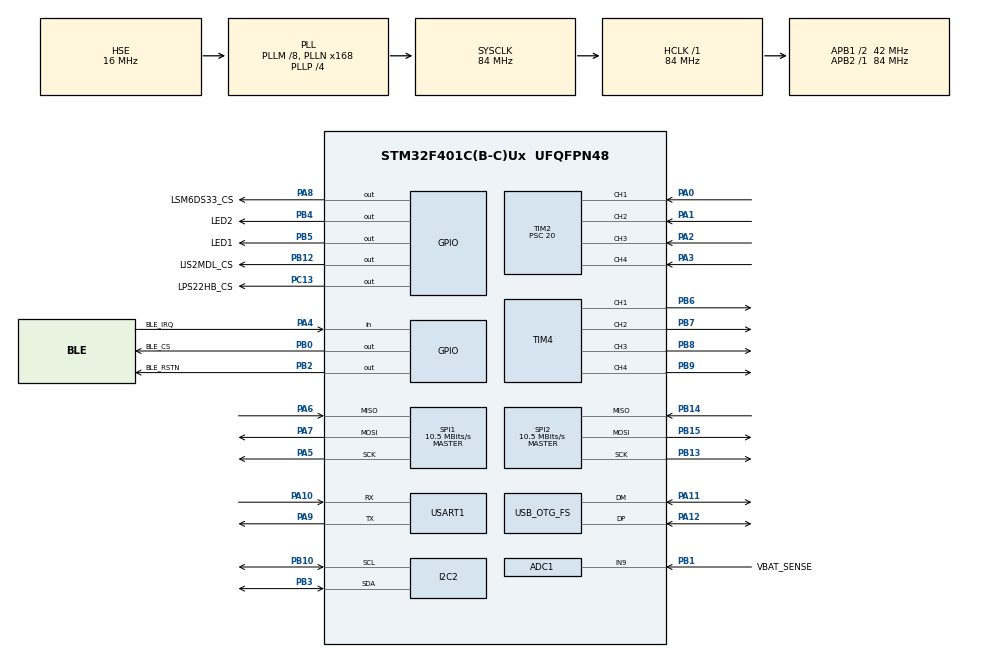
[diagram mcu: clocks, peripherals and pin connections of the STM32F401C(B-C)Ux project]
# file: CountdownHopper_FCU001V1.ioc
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ADC1.Channel-2\#ChannelRegularConversion=ADC_CHANNEL_9
ADC1.NbrOfConversionFlag=1
ADC1.Rank-2\#ChannelRegularConversion=1
ADC1.SamplingTime-2\#ChannelRegularConversion=ADC_SAMPLETIME_3CYCLES
ADC1.master=1
FREERTOS.Tasks01=defaultTask,0,128,StartDefaultTask,Default,NULL,Dynamic,NULL,NULL;blink,0,128,FRTOS_Blink,Default,NULL,Dynamic,NULL,NULL
FREERTOS.Timers01=BlinkTimer,Blink_LED1,osTimerPeriodic,Default,NULL,Dynamic,NULL
FREERTOS.configGENERATE_RUN_TIME_STATS=1
FREERTOS.configUSE_CO_ROUTINES=0
FREERTOS.configUSE_PREEMPTION=1
FREERTOS.configUSE_TICKLESS_IDLE=1
FREERTOS.configUSE_TICK_HOOK=0
FREERTOS.configUSE_TIMERS=1
Mcu.Family=STM32F4
Mcu.Name=STM32F401C(B-C)Ux
Mcu.Package=UFQFPN48
NVIC.PriorityGroup=NVIC_PRIORITYGROUP_4
PA0-WKUP.Signal=S_TIM2_CH1_ETR
PA1.Signal=S_TIM2_CH2
PA10.Mode=Asynchronous
PA10.Signal=USART1_RX
PA11.Mode=Device_Only
PA11.Signal=USB_OTG_FS_DM
PA12.Mode=Device_Only
PA12.Signal=USB_OTG_FS_DP
PA13.Mode=Serial_Wire
PA13.Signal=SYS_JTMS-SWDIO
PA14.Mode=Serial_Wire
PA14.Signal=SYS_JTCK-SWCLK
PA2.Signal=S_TIM2_CH3
PA3.Signal=S_TIM2_CH4
PA4.GPIO_Label=BLE_IRQ
PA4.Signal=GPIO_Input
PA5.Mode=Full_Duplex_Master
PA5.Signal=SPI1_SCK
PA6.Mode=Full_Duplex_Master
PA6.Signal=SPI1_MISO
PA7.Mode=Full_Duplex_Master
PA7.Signal=SPI1_MOSI
PA8.GPIO_Label=LSM6DS33_CS
PA8.Signal=GPIO_Output
PA9.Mode=Asynchronous
PA9.Signal=USART1_TX
PB0.GPIO_Label=BLE_CS
PB0.Signal=GPIO_Output
PB1.GPIO_Label=VBAT_SENSE
PB1.Signal=ADCx_IN9
PB10.Mode=I2C
PB10.Signal=I2C2_SCL
PB12.GPIO_Label=LIS2MDL_CS
PB12.Signal=GPIO_Output
PB13.Mode=Full_Duplex_Master
PB13.Signal=SPI2_SCK
PB14.Mode=Full_Duplex_Master
PB14.Signal=SPI2_MISO
PB15.Mode=Full_Duplex_Master
PB15.Signal=SPI2_MOSI
PB2.GPIO_Label=BLE_RSTN
PB2.Signal=GPIO_Output
PB3.Mode=I2C
PB3.Signal=I2C2_SDA
PB4.GPIO_Label=LED2
PB4.Signal=GPIO_Output
PB5.GPIO_Label=LED1
PB5.Signal=GPIO_Output
PB6.Signal=S_TIM4_CH1
PB7.Signal=S_TIM4_CH2
PB8.Signal=S_TIM4_CH3
PB9.Signal=S_TIM4_CH4
PC13-ANTI_TAMP.GPIO_Label=LPS22HB_CS
PC13-ANTI_TAMP.Signal=GPIO_Output
PC14-OSC32_IN.Mode=LSE-External-Clock-Source
PC14-OSC32_IN.Signal=RCC_OSC32_IN
PC15-OSC32_OUT.Mode=LSE-External-Clock-Source
PC15-OSC32_OUT.Signal=RCC_OSC32_OUT
PH0\ -\ OSC_IN.Mode=HSE-External-Oscillator
PH0\ -\ OSC_IN.Signal=RCC_OSC_IN
PH1\ -\ OSC_OUT.Mode=HSE-External-Oscillator
PH1\ -\ OSC_OUT.Signal=RCC_OSC_OUT
ProjectManager.HeapSize=0x200
ProjectManager.StackSize=0x400
ProjectManager.TargetToolchain=STM32CubeIDE
RCC.48MHZClocksFreq_Value=48000000
RCC.AHBFreq_Value=84000000
RCC.APB1CLKDivider=RCC_HCLK_DIV2
RCC.APB1Freq_Value=42000000
RCC.APB1TimFreq_Value=84000000
RCC.APB2Freq_Value=84000000
RCC.APB2TimFreq_Value=84000000
RCC.CortexFreq_Value=84000000
RCC.HCLKFreq_Value=84000000
RCC.HSE_VALUE=16000000
RCC.HSI_VALUE=16000000
RCC.LSE_VALUE=32768
RCC.PLLM=8
RCC.PLLN=168
RCC.PLLP=RCC_PLLP_DIV4
RCC.PLLQ=7
RCC.SYSCLKFreq_VALUE=84000000
RCC.SYSCLKSource=RCC_SYSCLKSOURCE_PLLCLK
RCC.VCOOutputFreq_Value=336000000
SH.ADCx_IN9.0=ADC1_IN9,IN9
SH.S_TIM2_CH1_ETR.0=TIM2_CH1,Input_Capture1_from_TI1
SH.S_TIM2_CH2.0=TIM2_CH2,Input_Capture2_from_TI2
SH.S_TIM2_CH3.0=TIM2_CH3,Input_Capture3_from_TI3
SH.S_TIM2_CH4.0=TIM2_CH4,Input_Capture4_from_TI4
SH.S_TIM4_CH1.0=TIM4_CH1,PWM Generation1 CH1
SH.S_TIM4_CH2.0=TIM4_CH2,PWM Generation2 CH2
SH.S_TIM4_CH3.0=TIM4_CH3,PWM Generation3 CH3
SH.S_TIM4_CH4.0=TIM4_CH4,PWM Generation4 CH4
SPI1.BaudRatePrescaler=SPI_BAUDRATEPRESCALER_8
SPI1.CalculateBaudRate=10.5 MBits/s
SPI1.Direction=SPI_DIRECTION_2LINES
SPI1.Mode=SPI_MODE_MASTER
SPI1.VirtualType=VM_MASTER
SPI2.BaudRatePrescaler=SPI_BAUDRATEPRESCALER_4
SPI2.CalculateBaudRate=10.5 MBits/s
SPI2.Direction=SPI_DIRECTION_2LINES
SPI2.Mode=SPI_MODE_MASTER
SPI2.VirtualType=VM_MASTER
TIM2.Channel-Input_Capture1_from_TI1=TIM_CHANNEL_1
TIM2.Channel-Input_Capture2_from_TI2=TIM_CHANNEL_2
TIM2.Channel-Input_Capture3_from_TI3=TIM_CHANNEL_3
TIM2.Channel-Input_Capture4_from_TI4=TIM_CHANNEL_4
TIM2.ICPolarity_CH1=TIM_INPUTCHANNELPOLARITY_BOTHEDGE
TIM2.ICPolarity_CH2=TIM_INPUTCHANNELPOLARITY_BOTHEDGE
TIM2.ICPolarity_CH3=TIM_INPUTCHANNELPOLARITY_BOTHEDGE
TIM2.ICPolarity_CH4=TIM_INPUTCHANNELPOLARITY_BOTHEDGE
TIM2.Prescaler=20
TIM4.Channel-PWM\ Generation1\ CH1=TIM_CHANNEL_1
TIM4.Channel-PWM\ Generation2\ CH2=TIM_CHANNEL_2
TIM4.Channel-PWM\ Generation3\ CH3=TIM_CHANNEL_3
TIM4.Channel-PWM\ Generation4\ CH4=TIM_CHANNEL_4
USART1.VirtualMode=VM_ASYNC
USB_OTG_FS.VirtualMode=Device_Only
VP_FREERTOS_VS_CMSIS_V1.Mode=CMSIS_V1
VP_TIM2_VS_ClockSourceITR.Mode=TriggerSource_ITR0
VP_TIM2_VS_ControllerModeClock.Mode=Clock Mode
VP_TIM4_VS_ClockSourceITR.Mode=TriggerSource_ITR0
VP_TIM4_VS_ControllerModeClock.Mode=Clock Mode
board=custom

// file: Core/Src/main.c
/* USER CODE BEGIN Header */
/**
  ******************************************************************************
  * @file           : main.c
  * @brief          : Main program body
  ******************************************************************************
  * @attention
  *
  * <h2><center>&copy; Copyright (c) 2020 STMicroelectronics.
  * All rights reserved.</center></h2>
  *
  * This software component is licensed by ST under BSD 3-Clause license,
  * the "License"; You may not use this file except in compliance with the
  * License. You may obtain a copy of the License at:
  *                        opensource.org/licenses/BSD-3-Clause
  *
  ******************************************************************************
  */
/* USER CODE END Header */

#include "main.h"
#include "cmsis_os.h"

ADC_HandleTypeDef hadc1;

I2C_HandleTypeDef hi2c2;

SPI_HandleTypeDef hspi1;
SPI_HandleTypeDef hspi2;

TIM_HandleTypeDef htim2;
TIM_HandleTypeDef htim4;

UART_HandleTypeDef huart1;

PCD_HandleTypeDef hpcd_USB_OTG_FS;

osThreadId defaultTaskHandle;
osThreadId blinkHandle;
osTimerId BlinkTimerHandle;

void SystemClock_Config(void);
static void MX_GPIO_Init(void);
static void MX_TIM4_Init(void);
static void MX_I2C2_Init(void);
static void MX_USB_OTG_FS_PCD_Init(void);
static void MX_USART1_UART_Init(void);
static void MX_SPI2_Init(void);
static void MX_ADC1_Init(void);
static void MX_SPI1_Init(void);
static void MX_TIM2_Init(void);
void StartDefaultTask(void const * argument);
void FRTOS_Blink(void const * argument);
void Blink_LED1(void const * argument);

int main(void)
{

  /* MCU Configuration--------------------------------------------------------*/

  /* Reset of all peripherals, Initializes the Flash interface and the Systick. */
  HAL_Init();

  /* Configure the system clock */
  SystemClock_Config();

  /* Initialize all configured peripherals */
  MX_GPIO_Init();
  MX_TIM4_Init();
  MX_I2C2_Init();
  MX_USB_OTG_FS_PCD_Init();
  MX_USART1_UART_Init();
  MX_SPI2_Init();
  MX_ADC1_Init();
  MX_SPI1_Init();
  MX_TIM2_Init();

  /* Create the timer(s) */
  /* definition and creation of BlinkTimer */
  osTimerDef(BlinkTimer, Blink_LED1);
  BlinkTimerHandle = osTimerCreate(osTimer(BlinkTimer), osTimerPeriodic, NULL);

  /* USER CODE BEGIN RTOS_TIMERS */

  // to the callback function
  /* USER CODE END RTOS_TIMERS */

  /* Create the thread(s) */
  /* definition and creation of defaultTask */
  osThreadDef(defaultTask, StartDefaultTask, osPriorityNormal, 0, 128);
  defaultTaskHandle = osThreadCreate(osThread(defaultTask), NULL);

  /* definition and creation of blink */
  osThreadDef(blink, FRTOS_Blink, osPriorityNormal, 0, 128);
  blinkHandle = osThreadCreate(osThread(blink), NULL);

  /* Start scheduler */
  osKernelStart();

  /* We should never get here as control is now taken by the scheduler */
  /* Infinite loop */
  while (1)
  {

  }
}

void SystemClock_Config(void)
{
  RCC_OscInitTypeDef RCC_OscInitStruct = {0};
  RCC_ClkInitTypeDef RCC_ClkInitStruct = {0};

  /** Configure the main internal regulator output voltage
  */
  __HAL_RCC_PWR_CLK_ENABLE();
  __HAL_PWR_VOLTAGESCALING_CONFIG(PWR_REGULATOR_VOLTAGE_SCALE2);
  /** Initializes the CPU, AHB and APB busses clocks
  */
  RCC_OscInitStruct.OscillatorType = RCC_OSCILLATORTYPE_HSE;
  RCC_OscInitStruct.HSEState = RCC_HSE_ON;
  RCC_OscInitStruct.PLL.PLLState = RCC_PLL_ON;
  RCC_OscInitStruct.PLL.PLLSource = RCC_PLLSOURCE_HSE;
  RCC_OscInitStruct.PLL.PLLM = 8;
  RCC_OscInitStruct.PLL.PLLN = 168;
  RCC_OscInitStruct.PLL.PLLP = RCC_PLLP_DIV4;
  RCC_OscInitStruct.PLL.PLLQ = 7;
  if (HAL_RCC_OscConfig(&RCC_OscInitStruct) != HAL_OK)
  {
    Error_Handler();
  }
  /** Initializes the CPU, AHB and APB busses clocks
  */
  RCC_ClkInitStruct.ClockType = RCC_CLOCKTYPE_HCLK|RCC_CLOCKTYPE_SYSCLK
                              |RCC_CLOCKTYPE_PCLK1|RCC_CLOCKTYPE_PCLK2;
  RCC_ClkInitStruct.SYSCLKSource = RCC_SYSCLKSOURCE_PLLCLK;
  RCC_ClkInitStruct.AHBCLKDivider = RCC_SYSCLK_DIV1;
  RCC_ClkInitStruct.APB1CLKDivider = RCC_HCLK_DIV2;
  RCC_ClkInitStruct.APB2CLKDivider = RCC_HCLK_DIV1;

  if (HAL_RCC_ClockConfig(&RCC_ClkInitStruct, FLASH_LATENCY_2) != HAL_OK)
  {
    Error_Handler();
  }
}

static void MX_ADC1_Init(void)
{

  ADC_ChannelConfTypeDef sConfig = {0};

  /** Configure the global features of the ADC (Clock, Resolution, Data Alignment and number of conversion)
  */
  hadc1.Instance = ADC1;
  hadc1.Init.ClockPrescaler = ADC_CLOCK_SYNC_PCLK_DIV4;
  hadc1.Init.Resolution = ADC_RESOLUTION_12B;
  hadc1.Init.ScanConvMode = DISABLE;
  hadc1.Init.ContinuousConvMode = DISABLE;
  hadc1.Init.DiscontinuousConvMode = DISABLE;
  hadc1.Init.ExternalTrigConvEdge = ADC_EXTERNALTRIGCONVEDGE_NONE;
  hadc1.Init.ExternalTrigConv = ADC_SOFTWARE_START;
  hadc1.Init.DataAlign = ADC_DATAALIGN_RIGHT;
  hadc1.Init.NbrOfConversion = 1;
  hadc1.Init.DMAContinuousRequests = DISABLE;
  hadc1.Init.EOCSelection = ADC_EOC_SINGLE_CONV;
  if (HAL_ADC_Init(&hadc1) != HAL_OK)
  {
    Error_Handler();
  }
  /** Configure for the selected ADC regular channel its corresponding rank in the sequencer and its sample time.
  */
  sConfig.Channel = ADC_CHANNEL_9;
  sConfig.Rank = 1;
  sConfig.SamplingTime = ADC_SAMPLETIME_3CYCLES;
  if (HAL_ADC_ConfigChannel(&hadc1, &sConfig) != HAL_OK)
  {
    Error_Handler();
  }

}

static void MX_I2C2_Init(void)
{

  hi2c2.Instance = I2C2;
  hi2c2.Init.ClockSpeed = 100000;
  hi2c2.Init.DutyCycle = I2C_DUTYCYCLE_2;
  hi2c2.Init.OwnAddress1 = 0;
  hi2c2.Init.AddressingMode = I2C_ADDRESSINGMODE_7BIT;
  hi2c2.Init.DualAddressMode = I2C_DUALADDRESS_DISABLE;
  hi2c2.Init.OwnAddress2 = 0;
  hi2c2.Init.GeneralCallMode = I2C_GENERALCALL_DISABLE;
  hi2c2.Init.NoStretchMode = I2C_NOSTRETCH_DISABLE;
  if (HAL_I2C_Init(&hi2c2) != HAL_OK)
  {
    Error_Handler();
  }

}

static void MX_SPI1_Init(void)
{

  /* SPI1 parameter configuration*/
  hspi1.Instance = SPI1;
  hspi1.Init.Mode = SPI_MODE_MASTER;
  hspi1.Init.Direction = SPI_DIRECTION_2LINES;
  hspi1.Init.DataSize = SPI_DATASIZE_8BIT;
  hspi1.Init.CLKPolarity = SPI_POLARITY_LOW;
  hspi1.Init.CLKPhase = SPI_PHASE_1EDGE;
  hspi1.Init.NSS = SPI_NSS_SOFT;
  hspi1.Init.BaudRatePrescaler = SPI_BAUDRATEPRESCALER_8;
  hspi1.Init.FirstBit = SPI_FIRSTBIT_MSB;
  hspi1.Init.TIMode = SPI_TIMODE_DISABLE;
  hspi1.Init.CRCCalculation = SPI_CRCCALCULATION_DISABLE;
  hspi1.Init.CRCPolynomial = 10;
  if (HAL_SPI_Init(&hspi1) != HAL_OK)
  {
    Error_Handler();
  }

}

static void MX_SPI2_Init(void)
{

  /* SPI2 parameter configuration*/
  hspi2.Instance = SPI2;
  hspi2.Init.Mode = SPI_MODE_MASTER;
  hspi2.Init.Direction = SPI_DIRECTION_2LINES;
  hspi2.Init.DataSize = SPI_DATASIZE_8BIT;
  hspi2.Init.CLKPolarity = SPI_POLARITY_LOW;
  hspi2.Init.CLKPhase = SPI_PHASE_1EDGE;
  hspi2.Init.NSS = SPI_NSS_SOFT;
  hspi2.Init.BaudRatePrescaler = SPI_BAUDRATEPRESCALER_4;
  hspi2.Init.FirstBit = SPI_FIRSTBIT_MSB;
  hspi2.Init.TIMode = SPI_TIMODE_DISABLE;
  hspi2.Init.CRCCalculation = SPI_CRCCALCULATION_DISABLE;
  hspi2.Init.CRCPolynomial = 10;
  if (HAL_SPI_Init(&hspi2) != HAL_OK)
  {
    Error_Handler();
  }

}

static void MX_TIM2_Init(void)
{

  TIM_SlaveConfigTypeDef sSlaveConfig = {0};
  TIM_MasterConfigTypeDef sMasterConfig = {0};
  TIM_IC_InitTypeDef sConfigIC = {0};

  htim2.Instance = TIM2;
  htim2.Init.Prescaler = 20;
  htim2.Init.CounterMode = TIM_COUNTERMODE_UP;
  htim2.Init.Period = 0;
  htim2.Init.ClockDivision = TIM_CLOCKDIVISION_DIV1;
  htim2.Init.AutoReloadPreload = TIM_AUTORELOAD_PRELOAD_DISABLE;
  if (HAL_TIM_Base_Init(&htim2) != HAL_OK)
  {
    Error_Handler();
  }
  if (HAL_TIM_IC_Init(&htim2) != HAL_OK)
  {
    Error_Handler();
  }
  sSlaveConfig.SlaveMode = TIM_SLAVEMODE_EXTERNAL1;
  sSlaveConfig.InputTrigger = TIM_TS_ITR0;
  if (HAL_TIM_SlaveConfigSynchro(&htim2, &sSlaveConfig) != HAL_OK)
  {
    Error_Handler();
  }
  sMasterConfig.MasterOutputTrigger = TIM_TRGO_RESET;
  sMasterConfig.MasterSlaveMode = TIM_MASTERSLAVEMODE_DISABLE;
  if (HAL_TIMEx_MasterConfigSynchronization(&htim2, &sMasterConfig) != HAL_OK)
  {
    Error_Handler();
  }
  sConfigIC.ICPolarity = TIM_INPUTCHANNELPOLARITY_BOTHEDGE;
  sConfigIC.ICSelection = TIM_ICSELECTION_DIRECTTI;
  sConfigIC.ICPrescaler = TIM_ICPSC_DIV1;
  sConfigIC.ICFilter = 0;
  if (HAL_TIM_IC_ConfigChannel(&htim2, &sConfigIC, TIM_CHANNEL_1) != HAL_OK)
  {
    Error_Handler();
  }
  if (HAL_TIM_IC_ConfigChannel(&htim2, &sConfigIC, TIM_CHANNEL_2) != HAL_OK)
  {
    Error_Handler();
  }
  if (HAL_TIM_IC_ConfigChannel(&htim2, &sConfigIC, TIM_CHANNEL_3) != HAL_OK)
  {
    Error_Handler();
  }
  if (HAL_TIM_IC_ConfigChannel(&htim2, &sConfigIC, TIM_CHANNEL_4) != HAL_OK)
  {
    Error_Handler();
  }

}

static void MX_TIM4_Init(void)
{

  TIM_SlaveConfigTypeDef sSlaveConfig = {0};
  TIM_MasterConfigTypeDef sMasterConfig = {0};
  TIM_OC_InitTypeDef sConfigOC = {0};

  htim4.Instance = TIM4;
  htim4.Init.Prescaler = 0;
  htim4.Init.CounterMode = TIM_COUNTERMODE_UP;
  htim4.Init.Period = 0;
  htim4.Init.ClockDivision = TIM_CLOCKDIVISION_DIV1;
  htim4.Init.AutoReloadPreload = TIM_AUTORELOAD_PRELOAD_DISABLE;
  if (HAL_TIM_Base_Init(&htim4) != HAL_OK)
  {
    Error_Handler();
  }
  if (HAL_TIM_PWM_Init(&htim4) != HAL_OK)
  {
    Error_Handler();
  }
  sSlaveConfig.SlaveMode = TIM_SLAVEMODE_EXTERNAL1;
  sSlaveConfig.InputTrigger = TIM_TS_ITR0;
  if (HAL_TIM_SlaveConfigSynchro(&htim4, &sSlaveConfig) != HAL_OK)
  {
    Error_Handler();
  }
  sMasterConfig.MasterOutputTrigger = TIM_TRGO_RESET;
  sMasterConfig.MasterSlaveMode = TIM_MASTERSLAVEMODE_DISABLE;
  if (HAL_TIMEx_MasterConfigSynchronization(&htim4, &sMasterConfig) != HAL_OK)
  {
    Error_Handler();
  }
  sConfigOC.OCMode = TIM_OCMODE_PWM1;
  sConfigOC.Pulse = 0;
  sConfigOC.OCPolarity = TIM_OCPOLARITY_HIGH;
  sConfigOC.OCFastMode = TIM_OCFAST_DISABLE;
  if (HAL_TIM_PWM_ConfigChannel(&htim4, &sConfigOC, TIM_CHANNEL_1) != HAL_OK)
  {
    Error_Handler();
  }
  if (HAL_TIM_PWM_ConfigChannel(&htim4, &sConfigOC, TIM_CHANNEL_2) != HAL_OK)
  {
    Error_Handler();
  }
  if (HAL_TIM_PWM_ConfigChannel(&htim4, &sConfigOC, TIM_CHANNEL_3) != HAL_OK)
  {
    Error_Handler();
  }
  if (HAL_TIM_PWM_ConfigChannel(&htim4, &sConfigOC, TIM_CHANNEL_4) != HAL_OK)
  {
    Error_Handler();
  }
  HAL_TIM_MspPostInit(&htim4);

}

static void MX_USART1_UART_Init(void)
{

  huart1.Instance = USART1;
  huart1.Init.BaudRate = 115200;
  huart1.Init.WordLength = UART_WORDLENGTH_8B;
  huart1.Init.StopBits = UART_STOPBITS_1;
  huart1.Init.Parity = UART_PARITY_NONE;
  huart1.Init.Mode = UART_MODE_TX_RX;
  huart1.Init.HwFlowCtl = UART_HWCONTROL_NONE;
  huart1.Init.OverSampling = UART_OVERSAMPLING_16;
  if (HAL_UART_Init(&huart1) != HAL_OK)
  {
    Error_Handler();
  }

}

static void MX_USB_OTG_FS_PCD_Init(void)
{

  hpcd_USB_OTG_FS.Instance = USB_OTG_FS;
  hpcd_USB_OTG_FS.Init.dev_endpoints = 4;
  hpcd_USB_OTG_FS.Init.speed = PCD_SPEED_FULL;
  hpcd_USB_OTG_FS.Init.dma_enable = DISABLE;
  hpcd_USB_OTG_FS.Init.phy_itface = PCD_PHY_EMBEDDED;
  hpcd_USB_OTG_FS.Init.Sof_enable = DISABLE;
  hpcd_USB_OTG_FS.Init.low_power_enable = DISABLE;
  hpcd_USB_OTG_FS.Init.lpm_enable = DISABLE;
  hpcd_USB_OTG_FS.Init.vbus_sensing_enable = DISABLE;
  hpcd_USB_OTG_FS.Init.use_dedicated_ep1 = DISABLE;
  if (HAL_PCD_Init(&hpcd_USB_OTG_FS) != HAL_OK)
  {
    Error_Handler();
  }

}

static void MX_GPIO_Init(void)
{
  GPIO_InitTypeDef GPIO_InitStruct = {0};

  /* GPIO Ports Clock Enable */
  __HAL_RCC_GPIOC_CLK_ENABLE();
  __HAL_RCC_GPIOH_CLK_ENABLE();
  __HAL_RCC_GPIOA_CLK_ENABLE();
  __HAL_RCC_GPIOB_CLK_ENABLE();

  /*Configure GPIO pin Output Level */
  HAL_GPIO_WritePin(LPS22HB_CS_GPIO_Port, LPS22HB_CS_Pin, GPIO_PIN_RESET);

  /*Configure GPIO pin Output Level */
  HAL_GPIO_WritePin(GPIOB, BLE_CS_Pin|BLE_RSTN_Pin|LIS2MDL_CS_Pin|LED2_Pin
                          |LED1_Pin, GPIO_PIN_RESET);

  /*Configure GPIO pin Output Level */
  HAL_GPIO_WritePin(LSM6DS33_CS_GPIO_Port, LSM6DS33_CS_Pin, GPIO_PIN_RESET);

  /*Configure GPIO pin : LPS22HB_CS_Pin */
  GPIO_InitStruct.Pin = LPS22HB_CS_Pin;
  GPIO_InitStruct.Mode = GPIO_MODE_OUTPUT_PP;
  GPIO_InitStruct.Pull = GPIO_NOPULL;
  GPIO_InitStruct.Speed = GPIO_SPEED_FREQ_LOW;
  HAL_GPIO_Init(LPS22HB_CS_GPIO_Port, &GPIO_InitStruct);

  /*Configure GPIO pin : BLE_IRQ_Pin */
  GPIO_InitStruct.Pin = BLE_IRQ_Pin;
  GPIO_InitStruct.Mode = GPIO_MODE_INPUT;
  GPIO_InitStruct.Pull = GPIO_NOPULL;
  HAL_GPIO_Init(BLE_IRQ_GPIO_Port, &GPIO_InitStruct);

  /*Configure GPIO pins : BLE_CS_Pin BLE_RSTN_Pin LIS2MDL_CS_Pin LED2_Pin
                           LED1_Pin */
  GPIO_InitStruct.Pin = BLE_CS_Pin|BLE_RSTN_Pin|LIS2MDL_CS_Pin|LED2_Pin
                          |LED1_Pin;
  GPIO_InitStruct.Mode = GPIO_MODE_OUTPUT_PP;
  GPIO_InitStruct.Pull = GPIO_NOPULL;
  GPIO_InitStruct.Speed = GPIO_SPEED_FREQ_LOW;
  HAL_GPIO_Init(GPIOB, &GPIO_InitStruct);

  /*Configure GPIO pin : LSM6DS33_CS_Pin */
  GPIO_InitStruct.Pin = LSM6DS33_CS_Pin;
  GPIO_InitStruct.Mode = GPIO_MODE_OUTPUT_PP;
  GPIO_InitStruct.Pull = GPIO_NOPULL;
  GPIO_InitStruct.Speed = GPIO_SPEED_FREQ_LOW;
  HAL_GPIO_Init(LSM6DS33_CS_GPIO_Port, &GPIO_InitStruct);

}

void StartDefaultTask(void const * argument)
{
  /* USER CODE BEGIN 5 */
    // to the callback function
	osTimerStart(BlinkTimerHandle, 1000);

  /* Infinite loop */
  for(;;)
  {
    osDelay(1);
  }
  /* USER CODE END 5 */
}

void FRTOS_Blink(void const * argument)
{
  /* USER CODE BEGIN FRTOS_Blink */

	for( ;; )
	{
	 // Wait for the next cycle.
		HAL_GPIO_TogglePin(GPIOB, LED2_Pin);
		osDelay(100);
	}
  /* USER CODE END FRTOS_Blink */
}

/* Blink_LED1 function */
void Blink_LED1(void const * argument)
{
  /* USER CODE BEGIN Blink_LED1 */
	HAL_GPIO_TogglePin(GPIOB, LED1_Pin);
  /* USER CODE END Blink_LED1 */
}

void Error_Handler(void)
{
}

/************************ (C) COPYRIGHT STMicroelectronics *****END OF FILE****/

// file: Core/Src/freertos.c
/* USER CODE BEGIN Header */
/**
  ******************************************************************************
  * File Name          : freertos.c
  * Description        : Code for freertos applications
  ******************************************************************************
  * @attention
  *
  * <h2><center>&copy; Copyright (c) 2020 STMicroelectronics.
  * All rights reserved.</center></h2>
  *
  * This software component is licensed by ST under Ultimate Liberty license
  * SLA0044, the "License"; You may not use this file except in compliance with
  * the License. You may obtain a copy of the License at:
  *                             www.st.com/SLA0044
  *
  ******************************************************************************
  */
/* USER CODE END Header */

#include "FreeRTOS.h"
#include "task.h"
#include "main.h"

/* Pre/Post sleep processing prototypes */
void PreSleepProcessing(uint32_t *ulExpectedIdleTime);
void PostSleepProcessing(uint32_t *ulExpectedIdleTime);

/* GetIdleTaskMemory prototype (linked to static allocation support) */
void vApplicationGetIdleTaskMemory( StaticTask_t **ppxIdleTaskTCBBuffer, StackType_t **ppxIdleTaskStackBuffer, uint32_t *pulIdleTaskStackSize );

/* GetTimerTaskMemory prototype (linked to static allocation support) */
void vApplicationGetTimerTaskMemory( StaticTask_t **ppxTimerTaskTCBBuffer, StackType_t **ppxTimerTaskStackBuffer, uint32_t *pulTimerTaskStackSize );

/* Hook prototypes */
void configureTimerForRunTimeStats(void);
unsigned long getRunTimeCounterValue(void);

/* USER CODE BEGIN 1 */
/* Functions needed when configGENERATE_RUN_TIME_STATS is on */
__weak void configureTimerForRunTimeStats(void)
{

}

__weak unsigned long getRunTimeCounterValue(void)
{
return 0;
}
/* USER CODE END 1 */

/* USER CODE BEGIN PREPOSTSLEEP */
__weak void PreSleepProcessing(uint32_t *ulExpectedIdleTime)
{
/* place for user code */
}

__weak void PostSleepProcessing(uint32_t *ulExpectedIdleTime)
{
/* place for user code */
}
/* USER CODE END PREPOSTSLEEP */

/* USER CODE BEGIN GET_IDLE_TASK_MEMORY */
static StaticTask_t xIdleTaskTCBBuffer;
static StackType_t xIdleStack[configMINIMAL_STACK_SIZE];

void vApplicationGetIdleTaskMemory( StaticTask_t **ppxIdleTaskTCBBuffer, StackType_t **ppxIdleTaskStackBuffer, uint32_t *pulIdleTaskStackSize )
{
  *ppxIdleTaskTCBBuffer = &xIdleTaskTCBBuffer;
  *ppxIdleTaskStackBuffer = &xIdleStack[0];
  *pulIdleTaskStackSize = configMINIMAL_STACK_SIZE;
  /* place for user code */
}
/* USER CODE END GET_IDLE_TASK_MEMORY */

/* USER CODE BEGIN GET_TIMER_TASK_MEMORY */
static StaticTask_t xTimerTaskTCBBuffer;
static StackType_t xTimerStack[configTIMER_TASK_STACK_DEPTH];

void vApplicationGetTimerTaskMemory( StaticTask_t **ppxTimerTaskTCBBuffer, StackType_t **ppxTimerTaskStackBuffer, uint32_t *pulTimerTaskStackSize )
{
  *ppxTimerTaskTCBBuffer = &xTimerTaskTCBBuffer;
  *ppxTimerTaskStackBuffer = &xTimerStack[0];
  *pulTimerTaskStackSize = configTIMER_TASK_STACK_DEPTH;
  /* place for user code */
}
/* USER CODE END GET_TIMER_TASK_MEMORY */

/************************ (C) COPYRIGHT STMicroelectronics *****END OF FILE****/
